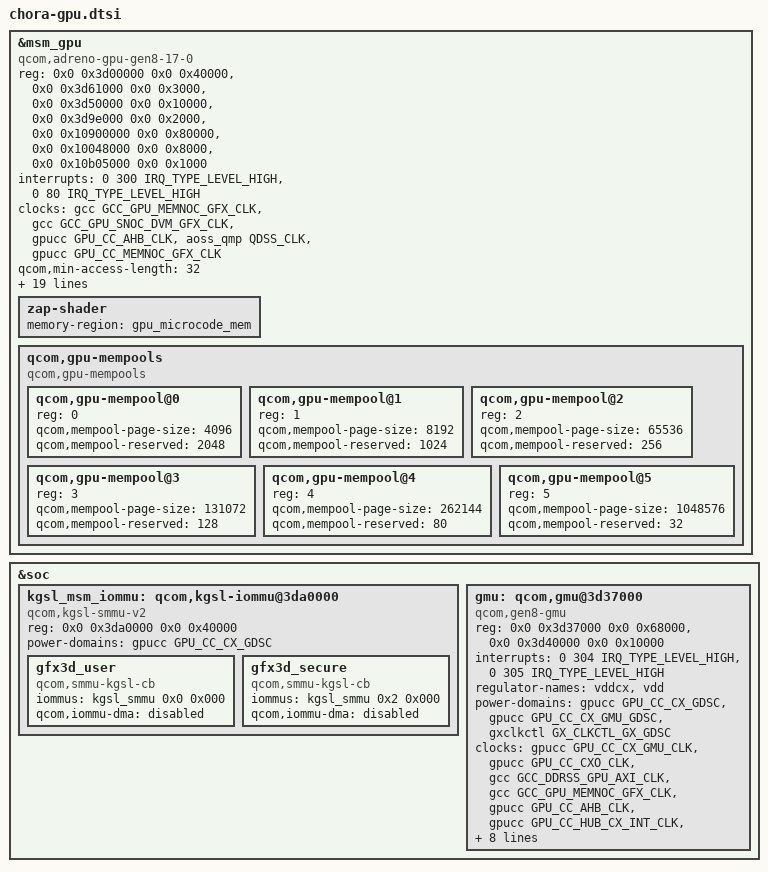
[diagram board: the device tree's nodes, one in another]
// SPDX-License-Identifier: BSD-3-Clause
/*
 * Copyright (c) Qualcomm Technologies, Inc. and/or its subsidiaries.
 */

#define MHZ_TO_KBPS(mhz, w) ((mhz * 1000000 * w) / (1024))

&msm_gpu {
	compatible = "qcom,adreno-gpu-gen8-17-0", "qcom,kgsl-3d0";
	status = "ok";
	reg = <0x0 0x3d00000 0x0 0x40000>, <0x0 0x3d61000 0x0 0x3000>,
		<0x0 0x3d50000 0x0 0x10000>, <0x0 0x3d9e000 0x0 0x2000>,
		<0x0 0x10900000 0x0 0x80000>, <0x0 0x10048000 0x0 0x8000>,
		<0x0 0x10b05000 0x0 0x1000>;
	reg-names = "kgsl_3d0_reg_memory", "cx_dbgc", "rscc", "cx_misc",
		"qdss_gfx", "qdss_etr", "qdss_tmc";

	interrupts = <0 300 IRQ_TYPE_LEVEL_HIGH>, <0 80 IRQ_TYPE_LEVEL_HIGH>;
	interrupt-names = "kgsl_3d0_irq", "cx_host_irq";

	clocks = <&gcc GCC_GPU_MEMNOC_GFX_CLK>,
			<&gcc GCC_GPU_SNOC_DVM_GFX_CLK>,
			<&gpucc GPU_CC_AHB_CLK>,
			<&aoss_qmp QDSS_CLK>,
			<&gpucc GPU_CC_MEMNOC_GFX_CLK>;
	clock-names = "gcc_gpu_memnoc_gfx",
			"gcc_gpu_snoc_dvm_gfx",
			"gpu_cc_ahb",
			"apb_pclk",
			"gpu_cc_memnoc_gfx_clk";

	qcom,min-access-length = <32>;

	qcom,ubwc-mode = <4>;

	nvmem-cells = <&gpu_speed_bin>;
	nvmem-cell-names = "speed_bin";

	qcom,tzone-names = "gpuss-0", "gpuss-1";

	interconnects = <&gem_noc MASTER_GFX3D &mc_virt SLAVE_EBI1>;
	interconnect-names = "gpu_icc_path";

	qcom,bus-table-cnoc =
		<0>,   /* Off */
		<100>; /* On */

	qcom,bus-table-ddr7 =
		<MHZ_TO_KBPS(0, 4)>,    /* index=0			*/
		<MHZ_TO_KBPS(200, 4)>,  /* index=1 LOW SVS	*/
		<MHZ_TO_KBPS(547, 4)>,	/* index=2 LOW SVS	*/
		<MHZ_TO_KBPS(768, 4)>,	/* index=3 SVS		*/
		<MHZ_TO_KBPS(1017, 4)>, /* index=4 SVS		*/
		<MHZ_TO_KBPS(1353, 4)>, /* index=5 SVS L1	*/
		<MHZ_TO_KBPS(1555, 4)>, /* index=6 NOM		*/
		<MHZ_TO_KBPS(1708, 4)>, /* index=7 NOM		*/
		<MHZ_TO_KBPS(2092, 4)>, /* index=8 TURBO	*/
		<MHZ_TO_KBPS(2133, 4)>, /* index=9 TURBO	*/
		<MHZ_TO_KBPS(4761, 4)>;	/* index=10 Dummy IB for max IB/AXI clock vote */

	qcom,bus-table-ddr8 =
		<MHZ_TO_KBPS(0, 4)>,	/* index=0			*/
		<MHZ_TO_KBPS(200, 4)>,	/* index=1 LOW SVS	*/
		<MHZ_TO_KBPS(547, 4)>,	/* index=2 LOW SVS	*/
		<MHZ_TO_KBPS(768, 4)>,	/* index=3 SVS		*/
		<MHZ_TO_KBPS(1555, 4)>,	/* index=4 SVS		*/
		<MHZ_TO_KBPS(1708, 4)>, /* index=5 SVS L1	*/
		<MHZ_TO_KBPS(2092, 4)>, /* index=6 NOM		*/
		<MHZ_TO_KBPS(2736, 4)>, /* index=7 TURBO	*/
		<MHZ_TO_KBPS(3196, 4)>, /* index=8 TURBO L1	*/
		<MHZ_TO_KBPS(4761, 4)>;	/* index=9 Dummy IB for max IB/AXI clock vote */

	zap-shader {
		memory-region = <&gpu_microcode_mem>;
	};

	qcom,gpu-mempools {
		#address-cells = <1>;
		#size-cells = <0>;
		compatible = "qcom,gpu-mempools";

		/* 4K Page Pool configuration */
		qcom,gpu-mempool@0 {
			reg = <0>;
			qcom,mempool-page-size = <4096>;
			qcom,mempool-reserved = <2048>;
		};
		/* 8K Page Pool configuration */
		qcom,gpu-mempool@1 {
			reg = <1>;
			qcom,mempool-page-size = <8192>;
			qcom,mempool-reserved = <1024>;
		};
		/* 64K Page Pool configuration */
		qcom,gpu-mempool@2 {
			reg = <2>;
			qcom,mempool-page-size = <65536>;
			qcom,mempool-reserved = <256>;
		};
		/* 128K Page Pool configuration */
		qcom,gpu-mempool@3 {
			reg = <3>;
			qcom,mempool-page-size = <131072>;
			qcom,mempool-reserved = <128>;
		};
		/* 256K Page Pool configuration */
		qcom,gpu-mempool@4 {
			reg = <4>;
			qcom,mempool-page-size = <262144>;
			qcom,mempool-reserved = <80>;
		};
		/* 1M Page Pool configuration */
		qcom,gpu-mempool@5 {
			reg = <5>;
			qcom,mempool-page-size = <1048576>;
			qcom,mempool-reserved = <32>;
		};
	};
};

&soc {
	kgsl_msm_iommu: qcom,kgsl-iommu@3da0000 {
		compatible = "qcom,kgsl-smmu-v2";
		reg = <0x0 0x3da0000 0x0 0x40000>;

		power-domains = <&gpucc GPU_CC_CX_GDSC>;

		gfx3d_user: gfx3d_user {
			compatible = "qcom,smmu-kgsl-cb";
			iommus = <&kgsl_smmu 0x0 0x000>;
			qcom,iommu-dma = "disabled";
		};

		gfx3d_secure: gfx3d_secure {
			compatible = "qcom,smmu-kgsl-cb";
			iommus = <&kgsl_smmu 0x2 0x000>;
			qcom,iommu-dma = "disabled";
		};
	};

	gmu: qcom,gmu@3d37000 {
		compatible = "qcom,gen8-gmu";

		reg = <0x0 0x3d37000 0x0 0x68000>,
			<0x0 0x3d40000 0x0 0x10000>;
		reg-names = "gmu", "gmu_ao_blk_dec0";

		interrupts = <0 304 IRQ_TYPE_LEVEL_HIGH>,
			<0 305 IRQ_TYPE_LEVEL_HIGH>;
		interrupt-names = "hfi", "gmu";

		regulator-names = "vddcx", "vdd";

		power-domains = <&gpucc GPU_CC_CX_GDSC>,
				<&gpucc GPU_CC_CX_GMU_GDSC>,
				<&gxclkctl GX_CLKCTL_GX_GDSC>;

		power-domain-names = "cx", "gmu_cx", "gx";

		clocks = <&gpucc GPU_CC_CX_GMU_CLK>,
			<&gpucc GPU_CC_CXO_CLK>,
			<&gcc GCC_DDRSS_GPU_AXI_CLK>,
			<&gcc GCC_GPU_MEMNOC_GFX_CLK>,
			<&gpucc GPU_CC_AHB_CLK>,
			<&gpucc GPU_CC_HUB_CX_INT_CLK>,
			<&gpucc GPU_CC_MEMNOC_GFX_CLK>;

		clock-names = "gmu_clk", "cxo_clk", "axi_clk",
			"memnoc_clk", "ahb_clk", "hub_clk", "gpu_cc_memnoc_gfx_clk";

		qcom,gmu-freq-table = <350000000 RPMH_REGULATOR_LEVEL_LOW_SVS>,
					<650000000 RPMH_REGULATOR_LEVEL_SVS>;

		qcom,gmu-perf-ddr-bw = <MHZ_TO_KBPS(768, 4)>;

		iommus = <&kgsl_smmu 0x5 0x000>;
		qcom,iommu-dma = "disabled";

		qcom,qmp = <&aoss_qmp>;
	};
};
